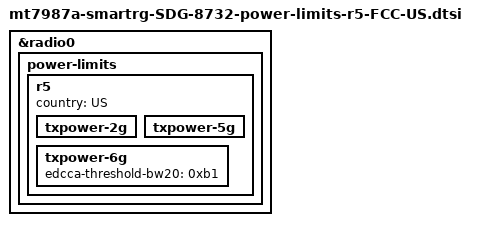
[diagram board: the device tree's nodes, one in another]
// SPDX-License-Identifier: (GPL-2.0 OR MIT)
/*
 * Copyright (C) 2026 SmartRG Inc.
 * Author: Chad Monroe <chad.monroe@smartrg.com>
 */

&radio0 {
	power-limits {
		r5 {
			country = "US";

			txpower-2g {
			};

			txpower-5g {
			};

			txpower-6g {
				edcca-threshold-bw20 = /bits/ 8 <0xb1>; /* -79 dBm */
			};
		};
	};
};
